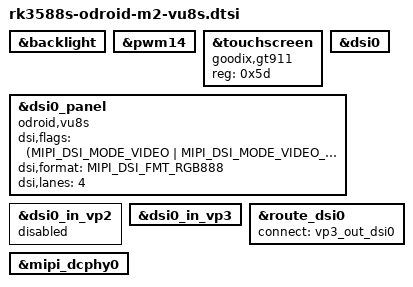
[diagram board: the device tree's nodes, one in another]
#include <dt-bindings/gpio/gpio.h>
#include <dt-bindings/pinctrl/rockchip.h>
#include <dt-bindings/display/drm_mipi_dsi.h>
#include <dt-bindings/display/rockchip_vop.h>
#include <dt-bindings/interrupt-controller/irq.h>
#include <dt-bindings/interrupt-controller/arm-gic.h>

&backlight {
	status = "okay";
};

&pwm14 {
	status = "okay";
};

&touchscreen {
	#address-cells = <1>;
	#size-cells = <0>;
	status = "okay";

	compatible = "goodix,gt911";
	reg = <0x5d>;
};

&dsi0 {
	status = "okay";
};

&dsi0_panel {
	status = "okay";
	compatible = "odroid,vu8s";

	dsi,flags = <(MIPI_DSI_MODE_VIDEO | MIPI_DSI_MODE_VIDEO_BURST |
			MIPI_DSI_MODE_NO_EOT_PACKET)>;
	dsi,format = <MIPI_DSI_FMT_RGB888>;
	dsi,lanes = <4>;
};

&dsi0_in_vp2 {
	status = "disabled";
};

&dsi0_in_vp3 {
	status = "okay";
};

&route_dsi0 {
	status = "okay";
	connect = <&vp3_out_dsi0>;
};

&mipi_dcphy0 {
	status = "okay";
};

&route_dsi0 {
	status = "okay";
};
